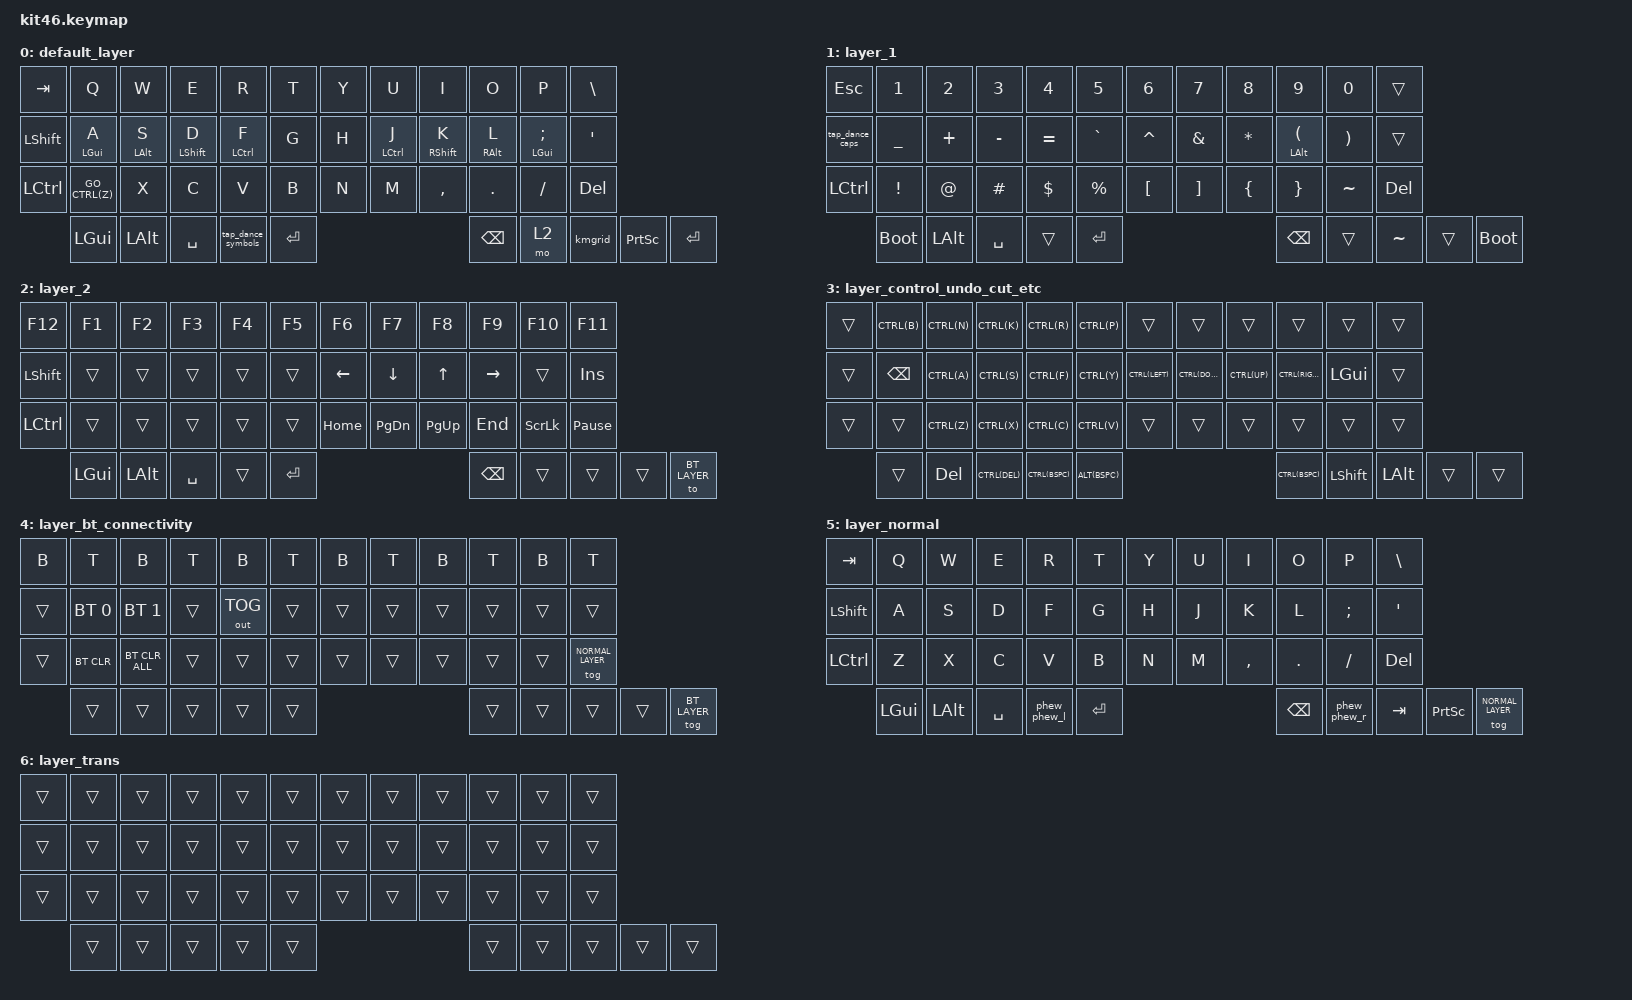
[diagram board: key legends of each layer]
/*
 * Copyright (c) 2021 The ZMK Contributors
 *
 * SPDX-License-Identifier: MIT
 */

#include <behaviors.dtsi>
#include <dt-bindings/zmk/keys.h>
#include <dt-bindings/zmk/bt.h>
#include <dt-bindings/zmk/outputs.h>

#define DEFAULT 0
#define SYMBOLS   1
#define DIRECTIONAL   2
#define CTRL_LAYER  3
#define BT_LAYER  4
#define NORMAL_LAYER  5


#define MO_TOG(layer) &mo_tog layer layer   // Macro to apply momentary-layer-on-hold/toggle-layer-on-tap to a specific layer
#define GO_CTRL(key) &go_ctrl CTRL_LAYER key
#define CTRL(key) &ctrl_ key
#define CTRL_ALT(key) &ctrl_atl_ key
#define ALT(key) &alt_ key
#define SHFT_GUI(key) &shift_gui_ key
#define GUI_(key) &gui_ key

/ {
    behaviors {
        mod_morph_undo: mod_morph_undo {
            compatible = "zmk,behavior-mod-morph";
            #binding-cells = <0>;
            bindings = <&kp W>, <&kp Z>;
            mods = <(MOD_LSFT)>;
        };
    };

    behaviors {
        mo_tog: behavior_mo_tog {
            compatible = "zmk,behavior-hold-tap";
            #binding-cells = <2>;
            flavor = "hold-preferred";
            tapping-term-ms = <200>;
            bindings = <&mo>, <&tog>;
        };
    };

    behaviors {
        go_ctrl: go_ctrl {
            compatible = "zmk,behavior-hold-tap";
            #binding-cells = <2>;
            flavor = "hold-preferred";
            tapping-term-ms = <200>;
            bindings = <&mo>, <&kp>;
            require-prior-idle-ms = <100>;
        };
    };

    macros {
        ctrl_: ctrl_ {
            compatible = "zmk,behavior-macro-one-param";
            #binding-cells = <1>;
            bindings
                = <&macro_press &kp LCTRL>
                , <&macro_param_1to1>
                , <&macro_press &kp MACRO_PLACEHOLDER>
                , <&macro_pause_for_release>
                , <&macro_param_1to1>
                , <&macro_release &kp MACRO_PLACEHOLDER &kp LCTRL>
                ;
        };

        alt_: alt_ {
            compatible = "zmk,behavior-macro-one-param";
            #binding-cells = <1>;
            bindings
                = <&macro_press &kp LALT>
                , <&macro_param_1to1>
                , <&macro_press &kp MACRO_PLACEHOLDER>
                , <&macro_pause_for_release>
                , <&macro_param_1to1>
                , <&macro_release &kp MACRO_PLACEHOLDER &kp LALT>
                ;
        };

        shift_gui_: shift_gui_ {
            compatible = "zmk,behavior-macro-one-param";
            #binding-cells = <1>;
            bindings
                = <&macro_press &kp LSHFT &kp LGUI>
                , <&macro_param_1to1>
                , <&macro_tap &kp MACRO_PLACEHOLDER>
                , <&macro_release &kp LSHFT &kp LGUI>
                ;
        };

        ctrl_atl_: ctrl_atl_ {
            compatible = "zmk,behavior-macro-one-param";
            #binding-cells = <1>;
            bindings
                = <&macro_press &kp LCTRL &kp LALT>
                , <&macro_param_1to1>
                , <&macro_tap &kp MACRO_PLACEHOLDER>
                , <&macro_release &kp LCTRL &kp LALT>
                ;
        };

        gui_: gui_ {
            compatible = "zmk,behavior-macro-one-param";
            #binding-cells = <1>;
            bindings
                = <&macro_press &kp LGUI>
                , <&macro_param_1to1>
                , <&macro_tap &kp MACRO_PLACEHOLDER>
                , <&macro_release &kp LGUI>
                ;
        };

        phew_phew_l: phew_phew_l {
            compatible = "zmk,behavior-macro";
            #binding-cells = <0>;
            bindings
                = <&macro_tap_time 5>
                , <&macro_wait_time 5>
                , <&macro_press &kp LSHFT>
                , <&macro_tap &kp P>
                , <&macro_tap &kp H>
                , <&macro_tap &kp E>
                , <&macro_tap &kp W>
                , <&macro_tap &kp SPACE>
                , <&macro_release &kp LSHFT>
                ;
        };

        phew_phew_r: phew_phew_r {
            compatible = "zmk,behavior-macro";
            #binding-cells = <0>;
            bindings
                = <&macro_tap_time 5>
                , <&macro_wait_time 5>
                , <&macro_tap &kp P>
                , <&macro_tap &kp H>
                , <&macro_tap &kp E>
                , <&macro_tap &kp W>
                , <&macro_tap &kp SPACE>
                ;
        };

        kmgrid: kmgrid {
            compatible = "zmk,behavior-macro";
            #binding-cells = <0>;
            bindings
                = <&macro_press &kp LSHFT>
                , <&macro_press &kp LALT>
                , <&macro_press &kp LCTRL>
                , <&macro_tap &kp F9>
                , <&macro_release &kp LCTRL>
                , <&macro_release &kp LALT>
                , <&macro_release &kp LSHFT>
                ;
        };
    };

    combos {
        compatible = "zmk,combos";
        combo_esc {
            timeout-ms = <50>;
            key-positions = <0 1 2 3>;
            bindings = <&kp ESC>;
        };
        combo_esc2 {
            timeout-ms = <50>;
            key-positions = <0 1 2 4>;
            bindings = <&kp ESC>;
        };
    };

    tap_dance_caps: tap_dance_caps {
        compatible = "zmk,behavior-tap-dance";
        #binding-cells = <0>;
        tapping-term-ms = <300>;
        bindings = <&kp LSHIFT>, <&kp LSHIFT>, <&kp CAPSLOCK>;
    };

    tap_dance_tab_tilde: tap_dance_tab_tilde {
        compatible = "zmk,behavior-tap-dance";
        #binding-cells = <0>;
        tapping-term-ms = <300>;
        bindings = <&kp T>, <&kp TILDE>;
    };

    tap_dance_symbols: tap_dance_symbols {
        compatible = "zmk,behavior-tap-dance";
        #binding-cells = <0>;
        tapping-term-ms = <200>;
        bindings = <&mo SYMBOLS>, <&mo SYMBOLS>, <&tog SYMBOLS>;
    };

    bhm: balanced_homerow_mods {
        compatible = "zmk,behavior-hold-tap";
        #binding-cells = <2>;
        tapping-term-ms = <350>;    // <---[[moderate duration]]
        quick-tap-ms = <0>;
        flavor = "balanced";
        bindings = <&kp>, <&kp>;
        require-prior-idle-ms = <150>;
    };

    thm: timeless_homerow_mod {
        compatible = "zmk,behavior-hold-tap";
        #binding-cells = <2>;
        tapping-term-ms = <200>;    // <---[[moderate duration]]
        require-prior-idle-ms = <150>;
        quick-tap-ms = <175>;
        flavor = "balanced";
        bindings = <&kp>, <&kp>;
        hold-trigger-on-release;
        require-prior-idle-ms = <100>;
    };

    gui_hm: gui_hm {
        compatible = "zmk,behavior-hold-tap";
        #binding-cells = <2>;
        tapping-term-ms = <350>;    // <---[[moderate duration]]
        quick-tap-ms = <0>;
        flavor = "tap-preferred";
        bindings = <&kp>, <&kp>;
        require-prior-idle-ms = <150>;
    };
};

/ {

    keymap {
        compatible = "zmk,keymap";

        default_layer { // layer 0
            bindings = <
        //╭──────────┬──────────┬──────────┬──────────┬──────────┬──────────╮   ╭──────────┬──────────┬──────────┬──────────┬──────────┬──────────╮
        //│  TAB     │  Q       │  W       │  E       │  R       │  T       │   │  Y       │  U       │  I       │  O       │  P       │ |  \     |
            &kp TAB    &kp Q     &kp W      &kp E      &kp R     &kp T          &kp Y      &kp U      &kp I      &kp O      &kp P       &kp BSLH
        //├──────────┼──────────┼──────────┼──────────┼──────────┼──────────┤   ├──────────┼──────────┼──────────┼──────────┼──────────┼──────────┤
        //│  LSHFT   │  A       │  S       │  D       │  F       │  G       │   │  H       │  J       │  K       │  L       │ ; :      │ ' "      │
    //        &kp LSHFT  &kp A      &kp S      &kp D      &kp F      &kp G          &kp H      &kp J      &kp K      &kp L      &kp SEMI   &kp SQT
           &kp LSHFT  &gui_hm LGUI A  &bhm LALT S      &bhm LSHFT D &bhm LCTRL F   &kp G          &kp H      &bhm LCTRL J      &bhm RSHFT K      &bhm RALT L      &gui_hm LGUI SEMI   &kp SQT

        //├──────────┼──────────┼──────────┼──────────┼──────────┼──────────┤   ├──────────┼──────────┼──────────┼──────────┼──────────┼──────────┤
        //│  LCTRL   │  Z       │  X       │  C       │  V       │  B       │   │  N       │  M       │ , <      │ . >      │ / ?      │  DEL     │
            &kp LCTRL  GO_CTRL(Z)      &kp X      &kp C      &kp V      &kp B          &kp N      &kp M      &kp COMMA  &kp DOT    &kp FSLH  &kp DEL
        //╰──────────┴──────────┴──────────┴──────────┼──────────┼──────────┤   ├──────────┴──────────┼──────────┼──────────┴──────────┴──────────╯
        //           │  GUI     │  ALT     │  SPACE   │  LAYER2  │  ENTER   │   │  BKSP    │  LAYER3  │  ESC     │ PRNT SCN │  ENTER   │
                       &kp LGUI   &kp LALT   &kp SPACE  &tap_dance_symbols      &kp RET        &kp BSPC   &mo 2      &kmgrid    &kp PSCRN  &kp ENTER
        //           ╰──────────┴──────────┴──────────┴──────────┴──────────╯   ╰──────────┴──────────┴──────────┴──────────┴──────────╯
            >;
        };

        layer_1 {
            bindings = <
        //╭──────────┬──────────┬──────────┬──────────┬──────────┬──────────╮   ╭──────────┬──────────┬──────────┬──────────┬──────────┬──────────╮
        //│  ESC     │  1       │  2       │  3       │  4       │  5       │   │  6       │  7       │  8       │  9       │  0       │          |
            &kp ESC    &kp N1     &kp N2     &kp N3     &kp N4     &kp N5         &kp N6     &kp N7     &kp N8     &kp N9     &kp N0     &trans
        //├──────────┼──────────┼──────────┼──────────┼──────────┼──────────┤   ├──────────┼──────────┼──────────┼──────────┼──────────┼──────────┤
        //│  LSHFT   │  _       │  +       │  -       │  =       │  `       │   │  ^       │  &       │  *       │  (       │  )       │          │
            &tap_dance_caps &kp UNDER  &kp PLUS  &kp MINUS  &kp EQUAL  &kp GRAVE      &kp CARET  &kp AMPS   &kp ASTRK  &bhm LALT LPAR   &kp RPAR   &trans
        //├──────────┼──────────┼──────────┼──────────┼──────────┼──────────┤   ├──────────┼──────────┼──────────┼──────────┼──────────┼──────────┤
        //│  LCTRL   │  !       │  @       │  #       │  $       │  %       │   │  [       │  ]       │  {       │  }       │  ~       │  DEL     │
            &kp LCTRL  &kp EXCL   &kp AT     &kp HASH   &kp DLLR   &kp PRCNT      &kp LBKT   &kp RBKT   &kp LBRC   &kp RBRC   &kp TILDE  &kp DEL
        //╰──────────┴──────────┴──────────┴──────────┼──────────┼──────────┤   ├──────────┴──────────┼──────────┼──────────┴──────────┴──────────╯
        //           │  GUI     │  ALT     │  SPACE   │  TRANS   │  ENTER   │   │  BKSP    │  TRANS   │  TRANS   │  TRANS   │  TRANS   │
                       &bootloader   &kp LALT   &kp SPACE  &trans     &kp RET        &kp BSPC   &trans    &kp TILDE     &trans     &bootloader
        //           ╰──────────┴──────────┴──────────┴──────────┴──────────╯   ╰──────────┴──────────┴──────────┴──────────┴──────────╯
            >;
        };

        layer_2 {
            bindings = <
        //╭──────────┬──────────┬──────────┬──────────┬──────────┬──────────╮   ╭──────────┬──────────┬──────────┬──────────┬──────────┬──────────╮
        //│  F12     │  F1      │  F2      │  F3      │  F4      │  F5      │   │  F6      │  F7      │  F8      │  F9      │  F10     │  F11     │
            &kp F12    &kp F1     &kp F2     &kp F3     &kp F4     &kp F5         &kp F6     &kp F7     &kp F8     &kp F9     &kp F10    &kp F11
        //├──────────┼──────────┼──────────┼──────────┼──────────┼──────────┤   ├──────────┼──────────┼──────────┼──────────┼──────────┼──────────┤
        //│  LSHFT   │ BT PRF 1 │ BT PRF 2 │  TRANS   │  TRANS   │  TRANS   │   │  LEFT    │  DOWN    │  UP      │  RIGHT   │          │  INSERT  │
            &kp LSHFT   &trans     &trans &trans &trans     &trans         &kp LEFT   &kp DOWN   &kp UP     &kp RIGHT   &trans    &kp INS
        //├──────────┼──────────┼──────────┼──────────┼──────────┼──────────┤   ├──────────┼──────────┼──────────┼──────────┼──────────┼──────────┤
        //│  LCTRL   │ BT CLR   │BT CLR ALL│  TRANS   │  TRANS   │  TRANS   │   │  HOME    │  PG DOWN │  PG UP   │  END     │ SCRLL LCK│ P_BRK    |
            &kp LCTRL   &trans     &trans &trans &trans     &trans         &kp HOME   &kp PG_DN  &kp PG_UP  &kp END    &kp SLCK   &kp PAUSE_BREAK
        //╰──────────┴──────────┴──────────┴──────────┼──────────┼──────────┤   ├──────────┴──────────┼──────────┼──────────┴──────────┴──────────╯
        //           │  GUI     │  ALT     │  SPACE   │  TRANS   │  ENTER   │   │  BKSP    │  TRANS   │  TRANS   │  TRANS   │  OUT_TOG   │
                       &kp LGUI   &kp LALT   &kp SPACE  &trans     &kp RET        &kp BSPC   &trans     &trans     &trans     &to BT_LAYER
        //           ╰──────────┴──────────┴──────────┴──────────┴──────────╯   ╰──────────┴──────────┴──────────┴──────────┴──────────╯
            >;
        };

        layer_control_undo_cut_etc { // layer 3
            bindings = <
        //╭──────────┬──────────┬──────────┬──────────┬──────────┬──────────╮   ╭──────────┬──────────┬──────────┬──────────┬──────────┬──────────╮
        //│  TRANS   │  TRANS   │  TRANS   │  TRANS   │  TRANS   │  TRANS   │   │  TRANS   │  TRANS   │  TRANS   │  TRANS   │  TRANS   │  TRANS   |
            &trans     CTRL(B)    CTRL(N) CTRL(K) CTRL(R) CTRL(P)          &trans &trans &trans &trans &trans &trans
        //├──────────┼──────────┼──────────┼──────────┼──────────┼──────────┤   ├──────────┼──────────┼──────────┼──────────┼──────────┼──────────┤
        //│  TRANS   │  TRANS   │  TRANS   │  TRANS   │  TRANS   │  TRANS   │   │  TRANS   │  TRANS   │  TRANS   │  TRANS   │  TRANS   │  TRANS   |
            &trans     &kp BSPC     CTRL(A) CTRL(S) CTRL(F) CTRL(Y)                 CTRL(LEFT) CTRL(DOWN) CTRL(UP) CTRL(RIGHT)    &kp LGUI     &trans
        //├──────────┼──────────┼──────────┼──────────┼──────────┼──────────┤   ├──────────┼──────────┼──────────┼──────────┼──────────┼──────────┤
        //│  TRANS   │  TRANS   │  TRANS   │  TRANS   │  TRANS   │  TRANS   │   │  TRANS   │  TRANS   │  TRANS   │  TRANS   │  TRANS   │  TRANS   |
            &trans     &trans     CTRL(Z) CTRL(X) CTRL(C) CTRL(V)                 &trans &trans &trans &trans    &trans     &trans
       //╰──────────┴──────────┴──────────┴──────────┼──────────┼──────────┤   ├──────────┴──────────┼──────────┼──────────┴──────────┴──────────╯
        //           │  TRANS   │  TRANS   │  TRANS   │  TRANS   │  TRANS   │   │  TRANS   │  TRANS   │  TRANS   │  TRANS   │  TRANS   │
                       &trans     &kp DEL     CTRL(DEL)      CTRL(BSPC) ALT(BSPC) CTRL(BSPC) &kp LSHFT &kp LALT     &trans     &trans
        //           ╰──────────┴──────────┴──────────┴──────────┴──────────╯   ╰──────────┴──────────┴──────────┴──────────┴──────────╯
            >;
        };

        layer_bt_connectivity { // layer 4
            bindings = <
        //╭──────────┬──────────┬──────────┬──────────┬──────────┬──────────╮   ╭──────────┬──────────┬──────────┬──────────┬──────────┬──────────╮
        //│  F12     │  F1      │  F2      │  F3      │  F4      │  F5      │   │  F6      │  F7      │  F8      │  F9      │  F10     │  F11     │
             &kp B &kp T &kp B &kp T &kp B &kp T &kp B &kp T &kp B &kp T &kp B &kp T
        //├──────────┼──────────┼──────────┼──────────┼──────────┼──────────┤   ├──────────┼──────────┼──────────┼──────────┼──────────┼──────────┤
        //│  LSHFT   │ BT PRF 1 │ BT PRF 2 │  TRANS   │  TRANS   │  TRANS   │   │  LEFT    │  DOWN    │  UP      │  RIGHT   │          │  INSERT  │
           &trans     &bt BT_SEL 0 &bt BT_SEL 1 &trans &out OUT_TOG   &trans      &trans     &trans     &trans     &trans     &trans     &trans
        //├──────────┼──────────┼──────────┼──────────┼──────────┼──────────┤   ├──────────┼──────────┼──────────┼──────────┼──────────┼──────────┤
        //│  LCTRL   │ BT CLR   │BT CLR ALL│  TRANS   │  TRANS   │  TRANS   │   │  HOME    │  PG DOWN │  PG UP   │  END     │ SCRLL LCK│ P_BRK    |
            &trans    &bt BT_CLR &bt BT_CLR_ALL &trans &trans     &trans          &trans     &trans     &trans     &trans     &trans     &tog NORMAL_LAYER
        //╰──────────┴──────────┴──────────┴──────────┼──────────┼──────────┤   ├──────────┴──────────┼──────────┼──────────┴──────────┴──────────╯
        //           │  GUI     │  ALT     │  SPACE   │  TRANS   │  ENTER   │   │  BKSP    │  TRANS   │  TRANS   │  TRANS   │  OUT_TOG   │
                       &trans     &trans     &trans     &trans      &trans        &trans     &trans     &trans     &trans     &tog BT_LAYER
        //           ╰──────────┴──────────┴──────────┴──────────┴──────────╯   ╰──────────┴──────────┴──────────┴──────────┴──────────╯
            >;
        };

        layer_normal { // layer 5
            bindings = <
        //╭──────────┬──────────┬──────────┬──────────┬──────────┬──────────╮   ╭──────────┬──────────┬──────────┬──────────┬──────────┬──────────╮
        //│  TAB     │  Q       │  W       │  E       │  R       │  T       │   │  Y       │  U       │  I       │  O       │  P       │ |  \     |
            &kp TAB    &kp Q     &kp W      &kp E      &kp R     &kp T          &kp Y      &kp U      &kp I      &kp O      &kp P       &kp BSLH
        //├──────────┼──────────┼──────────┼──────────┼──────────┼──────────┤   ├──────────┼──────────┼──────────┼──────────┼──────────┼──────────┤
        //│  LSHFT   │  A       │  S       │  D       │  F       │  G       │   │  H       │  J       │  K       │  L       │ ; :      │ ' "      │
            &kp LSHFT  &kp A      &kp S      &kp D      &kp F      &kp G          &kp H      &kp J      &kp K      &kp L      &kp SEMI   &kp SQT
        //├──────────┼──────────┼──────────┼──────────┼──────────┼──────────┤   ├──────────┼──────────┼──────────┼──────────┼──────────┼──────────┤
        //│  LCTRL   │  Z       │  X       │  C       │  V       │  B       │   │  N       │  M       │ , <      │ . >      │ / ?      │  DEL     │
            &kp LCTRL  &kp Z      &kp X      &kp C      &kp V      &kp B          &kp N      &kp M      &kp COMMA  &kp DOT    &kp FSLH  &kp DEL
        //╰──────────┴──────────┴──────────┴──────────┼──────────┼──────────┤   ├──────────┴──────────┼──────────┼──────────┴──────────┴──────────╯
        //           │  GUI     │  ALT     │  SPACE   │  LAYER2  │  ENTER   │   │  BKSP    │  LAYER3  │  ESC     │ PRNT SCN │  ENTER   │
                       &kp LGUI   &kp LALT   &kp SPACE  &phew_phew_l      &kp RET        &kp BSPC   &phew_phew_r      &kp TAB    &kp PSCRN  &tog NORMAL_LAYER
        //           ╰──────────┴──────────┴──────────┴──────────┴──────────╯   ╰──────────┴──────────┴──────────┴──────────┴──────────╯
            >;
        };

        layer_trans {
            bindings = <
        //╭──────────┬──────────┬──────────┬──────────┬──────────┬──────────╮   ╭──────────┬──────────┬──────────┬──────────┬──────────┬──────────╮
        //│  TRANS   │  TRANS   │  T  │  TRANS   │  TRANS   │  TRANS   │   │  TRANS   │  TRANS   │  TRANS   │  TRANS   │  TRANS   │  TRANS   |
            &trans     &trans     &trans     &trans     &trans     &trans         &trans     &trans     &trans     &trans     &trans     &trans
        //├──────────┼──────────┼──────────┼──────────┼──────────┼──────────┤   ├──────────┼──────────┼──────────┼──────────┼──────────┼──────────┤
        //│  TRANS   │  TRANS   │  TRANS   │  TRANS   │  TRANS   │  TRANS   │   │  TRANS   │  TRANS   │  TRANS   │  TRANS   │  TRANS   │  TRANS   |
            &trans     &trans     &trans     &trans     &trans     &trans         &trans     &trans     &trans     &trans     &trans     &trans
        //├──────────┼──────────┼──────────┼──────────┼──────────┼──────────┤   ├──────────┼──────────┼──────────┼──────────┼──────────┼──────────┤
        //│  TRANS   │  TRANS   │  TRANS   │  TRANS   │  TRANS   │  TRANS   │   │  TRANS   │  TRANS   │  TRANS   │  TRANS   │  TRANS   │  TRANS   |
            &trans     &trans     &trans     &trans     &trans     &trans         &trans     &trans     &trans     &trans     &trans     &trans
        //╰──────────┴──────────┴──────────┴──────────┼──────────┼──────────┤   ├──────────┴──────────┼──────────┼──────────┴──────────┴──────────╯
        //           │  TRANS   │  TRANS   │  TRANS   │  TRANS   │  TRANS   │   │  TRANS   │  TRANS   │  TRANS   │  TRANS   │  TRANS   │
                       &trans     &trans     &trans     &trans     &trans         &trans     &trans     &trans     &trans     &trans
        //           ╰──────────┴──────────┴──────────┴──────────┴──────────╯   ╰──────────┴──────────┴──────────┴──────────┴──────────╯
            >;
        };

    };
};
